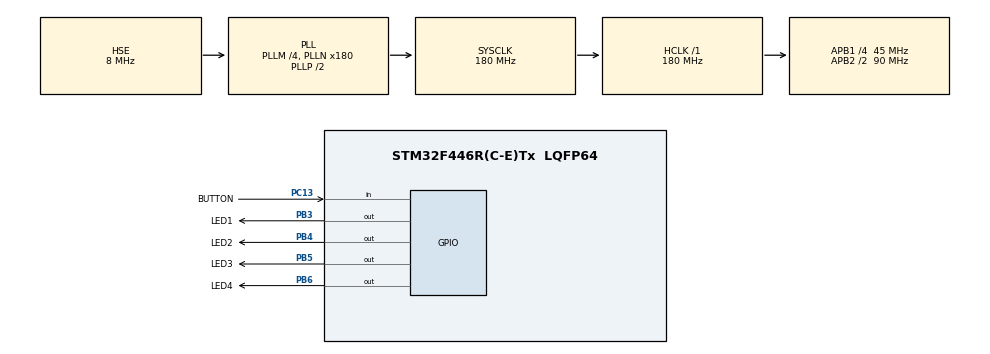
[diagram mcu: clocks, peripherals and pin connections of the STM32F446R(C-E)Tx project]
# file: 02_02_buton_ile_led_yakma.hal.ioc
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Mcu.Family=STM32F4
RCC.PLLSourceVirtual=RCC_PLLSOURCE_HSE
PH0-OSC_IN.Signal=RCC_OSC_IN
RCC.CortexFreq_Value=180000000
PC13.Signal=GPIO_Input
PB6.GPIO_Label=LED4
PC13.GPIO_Label=BUTTON
RCC.APB1CLKDivider=RCC_HCLK_DIV4
PB3.GPIO_Speed=GPIO_SPEED_FREQ_VERY_HIGH
RCC.SYSCLKSource=RCC_SYSCLKSOURCE_PLLCLK
ProjectManager.StackSize=0x400
PA13.Signal=SYS_JTMS-SWDIO
ProjectManager.TargetToolchain=STM32CubeIDE
RCC.HCLKFreq_Value=180000000
RCC.APB2TimFreq_Value=180000000
PB6.Signal=GPIO_Output
RCC.USBFreq_Value=180000000
RCC.AHBFreq_Value=180000000
PH0-OSC_IN.Mode=HSE-External-Oscillator
RCC.HSE_VALUE=8000000
board=custom
RCC.VCOOutputFreq_Value=360000000
PB4.GPIO_Speed=GPIO_SPEED_FREQ_VERY_HIGH
RCC.APB2Freq_Value=90000000
PB4.GPIO_Label=LED2
PA14.Mode=Serial_Wire
PC13.GPIO_PuPd=GPIO_PULLDOWN
PH1-OSC_OUT.Signal=RCC_OSC_OUT
PA13.Mode=Serial_Wire
Mcu.Name=STM32F446R(C-E)Tx
PH1-OSC_OUT.Mode=HSE-External-Oscillator
PB3.Signal=GPIO_Output
RCC.SYSCLKFreq_VALUE=180000000
Mcu.Package=LQFP64
PB5.Signal=GPIO_Output
PA14.Signal=SYS_JTCK-SWCLK
ProjectManager.HeapSize=0x200
PB5.GPIO_Speed=GPIO_SPEED_FREQ_VERY_HIGH
NVIC.PriorityGroup=NVIC_PRIORITYGROUP_4
RCC.APB2CLKDivider=RCC_HCLK_DIV2
PB5.GPIO_Label=LED3
RCC.PLLM=4
RCC.PLLN=180
RCC.APB1TimFreq_Value=90000000
PB6.GPIO_Speed=GPIO_SPEED_FREQ_VERY_HIGH
RCC.APB1Freq_Value=45000000
PB4.Signal=GPIO_Output
PB3.GPIO_Label=LED1

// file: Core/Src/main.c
/* USER CODE BEGIN Header */
/**
  ******************************************************************************
  * @file           : main.c
  * @brief          : Main program body
  ******************************************************************************
  * @attention
  *
  * <h2><center>&copy; Copyright (c) 2021 STMicroelectronics.
  * All rights reserved.</center></h2>
  *
  * This software component is licensed by ST under BSD 3-Clause license,
  * the "License"; You may not use this file except in compliance with the
  * License. You may obtain a copy of the License at:
  *                        opensource.org/licenses/BSD-3-Clause
  *
  ******************************************************************************
  */
/* USER CODE END Header */
#include "main.h"

/* USER CODE BEGIN PV */
int count=0;
/* USER CODE END PV */

void SystemClock_Config(void);
static void MX_GPIO_Init(void);

int main(void)
{

  /* MCU Configuration--------------------------------------------------------*/

  /* Reset of all peripherals, Initializes the Flash interface and the Systick. */
  HAL_Init();

  /* Configure the system clock */
  SystemClock_Config();

  /* Initialize all configured peripherals */
  MX_GPIO_Init();

  /* Infinite loop */
  while (1)
  {

    /* USER CODE BEGIN 3 */
	  if(HAL_GPIO_ReadPin(GPIOC, BUTTON_Pin))
	  {
		  while(HAL_GPIO_ReadPin(GPIOC, BUTTON_Pin));
		  HAL_Delay(100);
		  count++;
	  }

	  if(count % 2 == 1)
	  {
		  HAL_GPIO_WritePin(GPIOB, LED1_Pin | LED2_Pin | LED3_Pin | LED4_Pin,GPIO_PIN_SET);
	  }
	  else
	  {
		  HAL_GPIO_WritePin(GPIOB, LED1_Pin | LED2_Pin | LED3_Pin | LED4_Pin,GPIO_PIN_RESET);
	  }
  }
  /* USER CODE END 3 */
}

void SystemClock_Config(void)
{
  RCC_OscInitTypeDef RCC_OscInitStruct = {0};
  RCC_ClkInitTypeDef RCC_ClkInitStruct = {0};

  /** Configure the main internal regulator output voltage
  */
  __HAL_RCC_PWR_CLK_ENABLE();
  __HAL_PWR_VOLTAGESCALING_CONFIG(PWR_REGULATOR_VOLTAGE_SCALE1);
  /** Initializes the RCC Oscillators according to the specified parameters
  * in the RCC_OscInitTypeDef structure.
  */
  RCC_OscInitStruct.OscillatorType = RCC_OSCILLATORTYPE_HSE;
  RCC_OscInitStruct.HSEState = RCC_HSE_ON;
  RCC_OscInitStruct.PLL.PLLState = RCC_PLL_ON;
  RCC_OscInitStruct.PLL.PLLSource = RCC_PLLSOURCE_HSE;
  RCC_OscInitStruct.PLL.PLLM = 4;
  RCC_OscInitStruct.PLL.PLLN = 180;
  RCC_OscInitStruct.PLL.PLLP = RCC_PLLP_DIV2;
  RCC_OscInitStruct.PLL.PLLQ = 2;
  RCC_OscInitStruct.PLL.PLLR = 2;
  if (HAL_RCC_OscConfig(&RCC_OscInitStruct) != HAL_OK)
  {
    Error_Handler();
  }
  /** Activate the Over-Drive mode
  */
  if (HAL_PWREx_EnableOverDrive() != HAL_OK)
  {
    Error_Handler();
  }
  /** Initializes the CPU, AHB and APB buses clocks
  */
  RCC_ClkInitStruct.ClockType = RCC_CLOCKTYPE_HCLK|RCC_CLOCKTYPE_SYSCLK
                              |RCC_CLOCKTYPE_PCLK1|RCC_CLOCKTYPE_PCLK2;
  RCC_ClkInitStruct.SYSCLKSource = RCC_SYSCLKSOURCE_PLLCLK;
  RCC_ClkInitStruct.AHBCLKDivider = RCC_SYSCLK_DIV1;
  RCC_ClkInitStruct.APB1CLKDivider = RCC_HCLK_DIV4;
  RCC_ClkInitStruct.APB2CLKDivider = RCC_HCLK_DIV2;

  if (HAL_RCC_ClockConfig(&RCC_ClkInitStruct, FLASH_LATENCY_5) != HAL_OK)
  {
    Error_Handler();
  }
}

static void MX_GPIO_Init(void)
{
  GPIO_InitTypeDef GPIO_InitStruct = {0};

  /* GPIO Ports Clock Enable */
  __HAL_RCC_GPIOC_CLK_ENABLE();
  __HAL_RCC_GPIOH_CLK_ENABLE();
  __HAL_RCC_GPIOA_CLK_ENABLE();
  __HAL_RCC_GPIOB_CLK_ENABLE();

  /*Configure GPIO pin Output Level */
  HAL_GPIO_WritePin(GPIOB, LED1_Pin|LED2_Pin|LED3_Pin|LED4_Pin, GPIO_PIN_RESET);

  /*Configure GPIO pin : BUTTON_Pin */
  GPIO_InitStruct.Pin = BUTTON_Pin;
  GPIO_InitStruct.Mode = GPIO_MODE_INPUT;
  GPIO_InitStruct.Pull = GPIO_PULLDOWN;
  HAL_GPIO_Init(BUTTON_GPIO_Port, &GPIO_InitStruct);

  /*Configure GPIO pins : LED1_Pin LED2_Pin LED3_Pin LED4_Pin */
  GPIO_InitStruct.Pin = LED1_Pin|LED2_Pin|LED3_Pin|LED4_Pin;
  GPIO_InitStruct.Mode = GPIO_MODE_OUTPUT_PP;
  GPIO_InitStruct.Pull = GPIO_NOPULL;
  GPIO_InitStruct.Speed = GPIO_SPEED_FREQ_VERY_HIGH;
  HAL_GPIO_Init(GPIOB, &GPIO_InitStruct);

}

void Error_Handler(void)
{
  __disable_irq();
  while (1)
  {
  }
}

/************************ (C) COPYRIGHT STMicroelectronics *****END OF FILE****/
